# AE612FA0E5597LS0_CM55_HE_View register map
Vendor: Alif Semiconductor; Series: E6; File version: 1.0
CPU: CM55 r1p0, selectable endian, MPU, FPU, double-precision FPU, DSP, VTOR, 8 interrupt priority bits, 1 SAU regions
Registers are 32-bit, read-write, reset 0x0 unless marked. A register's access mark holds for its fields unless they carry their own. Offsets are from the block's base; [hi:lo] are bit positions; lines under a group give offsets from that group; {n}, {i} and the like mark numbered series; 'fields as' and 'values as' point back to an identical list.

## LPRTC0
Base 0x42000000
0x00 LPRTC_CCVR ro — Current Counter Value Register
  [31:0] CURRENT_COUNTER_VALUE — When read, this register contains the current value of the internal counter. This value is always read coherently.
0x04 LPRTC_CMR — Counter Match Register
  [31:0] COUNTER_MATCH — When the internal counter matches this value, an interrupt is generated, provided interrupt generation is enabled. When appropriate, this value is written coherently. Only when all the bytes are written, the value of this register is used by the interrupt detection logic.
0x08 LPRTC_CLR — Counter Load Register
  [31:0] COUNTER_LOAD — Loaded into the counter as counter load value, which is written coherently.
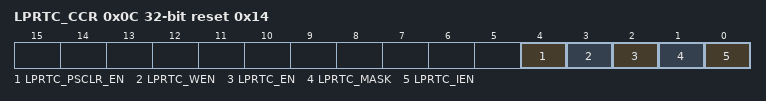
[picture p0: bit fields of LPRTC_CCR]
0x0C LPRTC_CCR reset 0x14 — Counter Control Register
  [4] LPRTC_PSCLR_EN — Controls the usage of the prescaler feature.
    0=Disables the prescaler; 1=Enables the prescaler
  [3] LPRTC_WEN — Controls the wrap enable. Forces the counter to wrap to 0 when a match occurs, instead of waiting until the maximum count is reached.
    0=Disables the wrap; 1=Enables the wrap
  [2] LPRTC_EN — Controls counting in the counter.
    0=Disables the counter; 1=Enables the counter
  [1] LPRTC_MASK — Controls the interrupt mask. Determines whether an internally generated interrupt shall assert the IRQ line.
    0=Unmasks the interrupt; 1=Masks the interrupt
  [0] LPRTC_IEN — Controls the interrupt enable.
    0=Disables the interrupt generation; 1=Enables the interrupt generation
0x10 LPRTC_STAT ro — Interrupt Status Register
  [0] LPRTC_STAT — Masked interrupt status.
    0=Interrupt is inactive. The IRQ line is not asserted.; 1=Interrupt is active. The IRQ line is asserted.
0x14 LPRTC_RSTAT ro — Interrupt Raw Status Register
  [0] LPRTC_RSTAT — Raw interrupt status.
    0=Interrupt is inactive; 1=Interrupt is active
0x18 LPRTC_EOI ro — End-of-Interrupt Register
  [0] LPRTC_EOI — By reading this bit, the match interrupt is cleared. Performing a read-to-clear on interrupt, the interrupt is cleared at the end of the read.
0x1C LPRTC_COMP_VERSION ro reset 0x3230372A — Component Version Register
  [31:0] LPRTC_COMP_VERSION — Component version
0x20 LPRTC_CPSR (reset mask 0xFFFF0000) — Counter Prescaler Register
  [15:0] COUNTER_PRESCALER_VALUE — Counter prescaler value. This bit field is used to prescale the rate at which the LPRTC counter updates. The prescaler value is in the range 1-65536. For example, when this bit field is programmed to 0x8000, and the prescaler is enabled and precise 32.768 kHz clock source is used, the counter increments at a 1 Hz rate. When appropriate, this bit field is written coherently. Only when all the bytes are written, the register is used by the prescaler counter logic. Note: System reset does not affect the value programmed in this bit field. The register will keep its last programmed value until the VDD_BAT power supply is removed.
0x24 LPRTC_CPCVR ro — Current Prescaler Counter Value Register
  [15:0] CURRENT_PRESCALER_COUNTER_VALUE — When read, this bit field provides the current value of the internal prescaler counter. This value is always read coherently.

## LPTIMER
Base 0x42001000
{0x0+0x14*i} LPTIMER_CHANNEL_CFG[{i}] (i=0..3) group
  0x00 LPTIMER_LOADCOUNT — Timer (n) Load Count Register
    [31:0] TIMERN_LOADCOUNT — Value to be loaded into Timer (n). This is the value from which counting commences. Any value written to this register is loaded into the associated timer.
  0x04 LPTIMER_CURRENTVAL ro reset 0x80000000 — Timer (n) Current Value Register
    [31:0] TIMERN_CURRENTVALUE — Current Value of Timer (n)
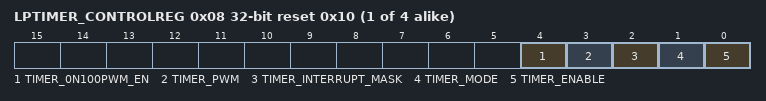
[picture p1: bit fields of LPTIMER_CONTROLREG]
  0x08 LPTIMER_CONTROLREG reset 0x10 — Timer (n) Control Register
    [4] TIMER_0N100PWM_EN ro — 0% and 100% PWM duty cycle mode for Timer (n). Hardcoded to enabled state to reduce software overhead.
      1=Enabled
    [3] TIMER_PWM — Pulse Width Modulation of Timer (n) toggle output.
      0=PWM is disabled (normal toggle); 1=PWM is enabled (PWM toggle)
    [2] TIMER_INTERRUPT_MASK — Timer interrupt mask for Timer (n).
      0=Timer (n) interrupt is unmasked; 1=Timer (n) interrupt is masked
    [1] TIMER_MODE — Timer mode for Timer (n). Note: All bits of the LPTIMERn_LOADCOUNT register must be set to 1 before enabling Timer (n) in free-running mode.
      0=Free-running count; 1=User-defined count
    [0] TIMER_ENABLE — Timer enable bit for Timer (n).
      0=Timer (n) is disabled; 1=Timer (n) is enabled
  0x0C LPTIMER_EOI ro — Timer (n) End-of-Interrupt Register
    [0] TIMERN_EOI — End-of-Interrupt for Timer (n).
  0x10 LPTIMER_INTSTAT ro — Timer (n) Interrupt Status Register
    [0] TIMERN_INTSTATUS — Interrupt status for Timer (n) after mask:
      0=Timer (n) interrupt is inactive. IRQ line is not asserted.; 1=Timer (n) interrupt is active. IRQ line is asserted.
0xA0 LPTIMERS_INTSTATUS ro — Timers Interrupt Status Register
  [3:0] TIMERS_INTSTATUS — Interrupt status of all timers after mask, where: Bit 3: LPTIMER3 Bit 2: LPTIMER2 Bit 1: LPTIMER1 Bit 0: LPTIMER0 For each bit:
    values as LPTIMER_CHANNEL_CFG[0].LPTIMER_INTSTAT.TIMERN_INTSTATUS
0xA4 LPTIMERS_EOI ro — Timers End-of-Interrupt Register
  [3:0] TIMERS_EOI — End-of-Interrupt for all timers, where: Bit 3: LPTIMER3 Bit 2: LPTIMER2 Bit 1: LPTIMER1 Bit 0: LPTIMER0
0xA8 LPTIMERS_RAWINTSTATUS ro — Timers Raw Interrupt Status Register
  [3:0] TIMERS_RAWINTSTAT — Raw interrupt status of all timers, where: Bit 3: LPTIMER3 Bit 2: LPTIMER2 Bit 1: LPTIMER1 Bit 0: LPTIMER0 For each bit:
    0=Raw Timer (n) interrupt is inactive; 1=Raw Timer (n) interrupt is active
0xAC LPTIMERS_COMP_VERSION ro reset 0x3231322A — LPTIMER Component Version
  [31:0] TIMERS_COMP_VERSION — LPTIMER version number
{0xB0+4i} LPTIMER_LOADCOUNT2[{i}] (i=0..3) — Timer (n) Load Count2 Register
  [31:0] TIMERN_LOADCOUNT2 — Value to be loaded into Timer (n) when toggle output changes from 0 to 1. This value determines the width of the high period of the toggle output.
